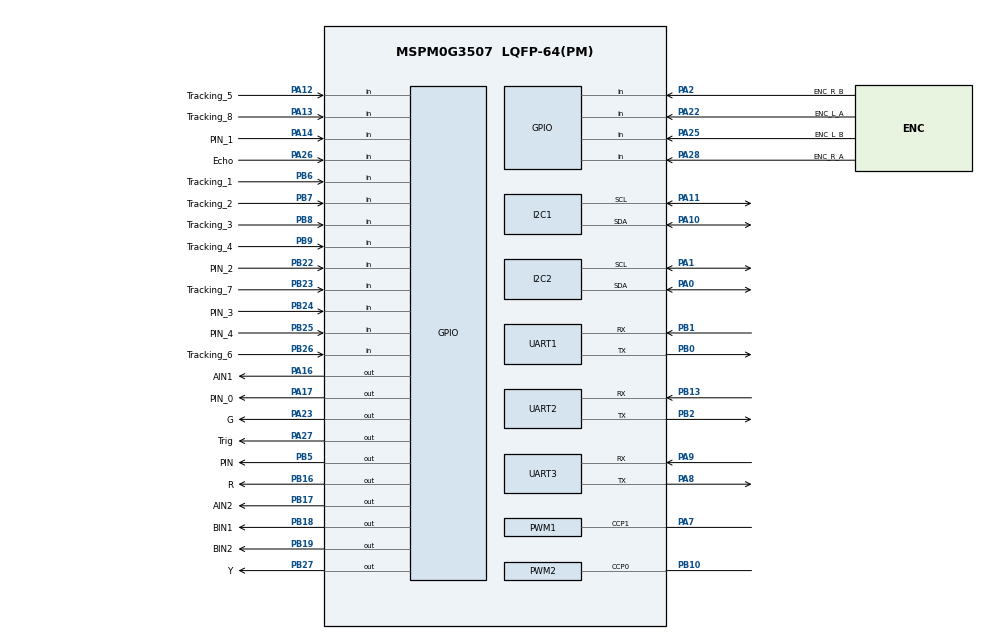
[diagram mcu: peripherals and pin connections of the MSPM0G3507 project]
/**
 * These arguments were used when this file was generated. They will be automatically applied on subsequent loads
 * via the GUI or CLI. Run CLI with '--help' for additional information on how to override these arguments.
 * @cliArgs --device "MSPM0G350X" --part "Default" --package "LQFP-64(PM)" --product "mspm0_sdk@2.10.00.04"
 * @v2CliArgs --device "MSPM0G3507" --package "LQFP-64(PM)" --product "mspm0_sdk@2.10.00.04"
 * @versions {"tool":"1.27.0+4565"}
 */

/**
 * Import the modules used in this configuration.
 */
const GPIO    = scripting.addModule("/ti/driverlib/GPIO", {}, false);
const GPIO1   = GPIO.addInstance();
const GPIO2   = GPIO.addInstance();
const GPIO3   = GPIO.addInstance();
const GPIO4   = GPIO.addInstance();
const GPIO5   = GPIO.addInstance();
const GPIO6   = GPIO.addInstance();
const GPIO7   = GPIO.addInstance();
const I2C     = scripting.addModule("/ti/driverlib/I2C", {}, false);
const I2C1    = I2C.addInstance();
const I2C2    = I2C.addInstance();
const PWM     = scripting.addModule("/ti/driverlib/PWM", {}, false);
const PWM1    = PWM.addInstance();
const PWM2    = PWM.addInstance();
const SYSCTL  = scripting.addModule("/ti/driverlib/SYSCTL");
const SYSTICK = scripting.addModule("/ti/driverlib/SYSTICK");
const TIMER   = scripting.addModule("/ti/driverlib/TIMER", {}, false);
const TIMER1  = TIMER.addInstance();
const UART    = scripting.addModule("/ti/driverlib/UART", {}, false);
const UART1   = UART.addInstance();
const UART2   = UART.addInstance();
const UART3   = UART.addInstance();

/**
 * Write custom configuration values to the imported modules.
 */
GPIO1.$name                               = "Motor_IO";
GPIO1.associatedPins.create(8);
GPIO1.associatedPins[0].$name             = "AIN1";
GPIO1.associatedPins[0].internalResistor  = "PULL_DOWN";
GPIO1.associatedPins[0].pin.$assign       = "PA16";
GPIO1.associatedPins[1].$name             = "AIN2";
GPIO1.associatedPins[1].internalResistor  = "PULL_DOWN";
GPIO1.associatedPins[1].pin.$assign       = "PB17";
GPIO1.associatedPins[2].$name             = "BIN1";
GPIO1.associatedPins[2].internalResistor  = "PULL_DOWN";
GPIO1.associatedPins[2].pin.$assign       = "PB18";
GPIO1.associatedPins[3].$name             = "BIN2";
GPIO1.associatedPins[3].internalResistor  = "PULL_DOWN";
GPIO1.associatedPins[3].pin.$assign       = "PB19";
GPIO1.associatedPins[4].$name             = "ENC_R_A";
GPIO1.associatedPins[4].direction         = "INPUT";
GPIO1.associatedPins[4].interruptEn       = true;
GPIO1.associatedPins[4].interruptPriority = "0";
GPIO1.associatedPins[4].polarity          = "RISE";
GPIO1.associatedPins[4].inputFilter       = "3_CYCLES";
GPIO1.associatedPins[4].pin.$assign       = "PA28";
GPIO1.associatedPins[5].$name             = "ENC_L_A";
GPIO1.associatedPins[5].direction         = "INPUT";
GPIO1.associatedPins[5].interruptEn       = true;
GPIO1.associatedPins[5].interruptPriority = "0";
GPIO1.associatedPins[5].polarity          = "RISE";
GPIO1.associatedPins[5].inputFilter       = "3_CYCLES";
GPIO1.associatedPins[5].pin.$assign       = "PA22";
GPIO1.associatedPins[6].$name             = "ENC_R_B";
GPIO1.associatedPins[6].direction         = "INPUT";
GPIO1.associatedPins[6].pin.$assign       = "PA2";
GPIO1.associatedPins[7].$name             = "ENC_L_B";
GPIO1.associatedPins[7].direction         = "INPUT";
GPIO1.associatedPins[7].pin.$assign       = "PA25";

const Board = scripting.addModule("/ti/driverlib/Board", {}, false);

GPIO2.$name                              = "Key";
GPIO2.associatedPins.create(4);
GPIO2.associatedPins[0].$name            = "PIN_1";
GPIO2.associatedPins[0].direction        = "INPUT";
GPIO2.associatedPins[0].internalResistor = "PULL_UP";
GPIO2.associatedPins[0].pin.$assign      = "PA14";
GPIO2.associatedPins[1].$name            = "PIN_2";
GPIO2.associatedPins[1].direction        = "INPUT";
GPIO2.associatedPins[1].internalResistor = "PULL_UP";
GPIO2.associatedPins[1].pin.$assign      = "PB22";
GPIO2.associatedPins[2].$name            = "PIN_3";
GPIO2.associatedPins[2].direction        = "INPUT";
GPIO2.associatedPins[2].internalResistor = "PULL_UP";
GPIO2.associatedPins[2].pin.$assign      = "PB24";
GPIO2.associatedPins[3].$name            = "PIN_4";
GPIO2.associatedPins[3].direction        = "INPUT";
GPIO2.associatedPins[3].internalResistor = "PULL_UP";
GPIO2.associatedPins[3].pin.$assign      = "PB25";

GPIO3.$name                              = "Tracking";
GPIO3.associatedPins.create(8);
GPIO3.associatedPins[0].$name            = "Tracking_1";
GPIO3.associatedPins[0].direction        = "INPUT";
GPIO3.associatedPins[0].internalResistor = "PULL_DOWN";
GPIO3.associatedPins[0].pin.$assign      = "PB6";
GPIO3.associatedPins[1].$name            = "Tracking_2";
GPIO3.associatedPins[1].internalResistor = "PULL_DOWN";
GPIO3.associatedPins[1].direction        = "INPUT";
GPIO3.associatedPins[1].pin.$assign      = "PB7";
GPIO3.associatedPins[2].$name            = "Tracking_3";
GPIO3.associatedPins[2].internalResistor = "PULL_DOWN";
GPIO3.associatedPins[2].direction        = "INPUT";
GPIO3.associatedPins[2].pin.$assign      = "PB8";
GPIO3.associatedPins[3].$name            = "Tracking_4";
GPIO3.associatedPins[3].internalResistor = "PULL_DOWN";
GPIO3.associatedPins[3].direction        = "INPUT";
GPIO3.associatedPins[3].pin.$assign      = "PB9";
GPIO3.associatedPins[4].$name            = "Tracking_5";
GPIO3.associatedPins[4].internalResistor = "PULL_DOWN";
GPIO3.associatedPins[4].direction        = "INPUT";
GPIO3.associatedPins[4].pin.$assign      = "PA12";
GPIO3.associatedPins[5].$name            = "Tracking_6";
GPIO3.associatedPins[5].internalResistor = "PULL_DOWN";
GPIO3.associatedPins[5].direction        = "INPUT";
GPIO3.associatedPins[5].pin.$assign      = "PB26";
GPIO3.associatedPins[6].$name            = "Tracking_7";
GPIO3.associatedPins[6].direction        = "INPUT";
GPIO3.associatedPins[6].internalResistor = "PULL_DOWN";
GPIO3.associatedPins[6].pin.$assign      = "PB23";
GPIO3.associatedPins[7].$name            = "Tracking_8";
GPIO3.associatedPins[7].internalResistor = "PULL_DOWN";
GPIO3.associatedPins[7].direction        = "INPUT";
GPIO3.associatedPins[7].pin.$assign      = "PA13";

GPIO4.$name                         = "SR04";
GPIO4.associatedPins.create(2);
GPIO4.associatedPins[0].$name       = "Trig";
GPIO4.associatedPins[0].pin.$assign = "PA27";
GPIO4.associatedPins[1].$name       = "Echo";
GPIO4.associatedPins[1].direction   = "INPUT";
GPIO4.associatedPins[1].pin.$assign = "PA26";

GPIO5.$name                         = "LED";
GPIO5.associatedPins.create(3);
GPIO5.associatedPins[0].$name       = "G";
GPIO5.associatedPins[0].pin.$assign = "PA23";
GPIO5.associatedPins[1].$name       = "Y";
GPIO5.associatedPins[1].pin.$assign = "PB27";
GPIO5.associatedPins[2].$name       = "R";
GPIO5.associatedPins[2].pin.$assign = "PB16";

GPIO6.$name                         = "Buzzer";
GPIO6.associatedPins[0].$name       = "PIN";
GPIO6.associatedPins[0].pin.$assign = "PB5";

GPIO7.$name                          = "GPIO_GRP_0";
GPIO7.associatedPins[0].$name        = "PIN_0";
GPIO7.associatedPins[0].initialValue = "SET";
GPIO7.associatedPins[0].pin.$assign  = "PA17";

I2C1.$name                             = "OLED";
I2C1.basicEnableController             = true;
I2C1.basicControllerStandardBusSpeed   = "Fast";
I2C1.peripheral.sdaPin.$assign         = "PA10";
I2C1.peripheral.sclPin.$assign         = "PA11";
I2C1.sdaPinConfig.$name                = "ti_driverlib_gpio_GPIOPinGeneric0";
I2C1.sdaPinConfig.hideOutputInversion  = scripting.forceWrite(false);
I2C1.sdaPinConfig.onlyInternalResistor = scripting.forceWrite(false);
I2C1.sdaPinConfig.passedPeripheralType = scripting.forceWrite("Digital");
I2C1.sclPinConfig.hideOutputInversion  = scripting.forceWrite(false);
I2C1.sclPinConfig.onlyInternalResistor = scripting.forceWrite(false);
I2C1.sclPinConfig.passedPeripheralType = scripting.forceWrite("Digital");
I2C1.sclPinConfig.$name                = "ti_driverlib_gpio_GPIOPinGeneric2";

I2C2.$name                             = "MPU6050_JY61P_Tracking";
I2C2.basicEnableController             = true;
I2C2.basicControllerStandardBusSpeed   = "Fast";
I2C2.intController                     = ["ARBITRATION_LOST","NACK","RXFIFO_TRIGGER","RX_DONE","TX_DONE"];
I2C2.peripheral.$assign                = "I2C0";
I2C2.peripheral.sdaPin.$assign         = "PA0";
I2C2.peripheral.sclPin.$assign         = "PA1";
I2C2.sdaPinConfig.hideOutputInversion  = scripting.forceWrite(false);
I2C2.sdaPinConfig.onlyInternalResistor = scripting.forceWrite(false);
I2C2.sdaPinConfig.passedPeripheralType = scripting.forceWrite("Digital");
I2C2.sdaPinConfig.$name                = "ti_driverlib_gpio_GPIOPinGeneric8";
I2C2.sclPinConfig.hideOutputInversion  = scripting.forceWrite(false);
I2C2.sclPinConfig.onlyInternalResistor = scripting.forceWrite(false);
I2C2.sclPinConfig.passedPeripheralType = scripting.forceWrite("Digital");
I2C2.sclPinConfig.$name                = "ti_driverlib_gpio_GPIOPinGeneric9";

PWM1.$name                              = "Motor_Left";
PWM1.clockDivider                       = 8;
PWM1.timerStartTimer                    = true;
PWM1.pwmMode                            = "EDGE_ALIGN_UP";
PWM1.ccIndex                            = [1];
PWM1.ccp1PinConfig.$name                = "ti_driverlib_gpio_GPIOPinGeneric5";
PWM1.ccp1PinConfig.direction            = scripting.forceWrite("OUTPUT");
PWM1.ccp1PinConfig.hideOutputInversion  = scripting.forceWrite(false);
PWM1.ccp1PinConfig.onlyInternalResistor = scripting.forceWrite(false);
PWM1.ccp1PinConfig.passedPeripheralType = scripting.forceWrite("Digital");
PWM1.peripheral.$assign                 = "TIMA0";
PWM1.peripheral.ccp1Pin.$assign         = "PA7";
PWM1.PWM_CHANNEL_1.$name                = "ti_driverlib_pwm_PWMTimerCC1";
PWM1.PWM_CHANNEL_1.ccValue              = 500;

PWM2.$name                              = "Motor_Right";
PWM2.clockDivider                       = 8;
PWM2.timerStartTimer                    = true;
PWM2.pwmMode                            = "EDGE_ALIGN_UP";
PWM2.ccIndex                            = [0];
PWM2.PWM_CHANNEL_0.$name                = "ti_driverlib_pwm_PWMTimerCC0";
PWM2.PWM_CHANNEL_0.dutyCycle            = 50;
PWM2.ccp0PinConfig.direction            = scripting.forceWrite("OUTPUT");
PWM2.ccp0PinConfig.hideOutputInversion  = scripting.forceWrite(false);
PWM2.ccp0PinConfig.onlyInternalResistor = scripting.forceWrite(false);
PWM2.ccp0PinConfig.passedPeripheralType = scripting.forceWrite("Digital");
PWM2.ccp0PinConfig.$name                = "ti_driverlib_gpio_GPIOPinGeneric4";
PWM2.peripheral.$assign                 = "TIMG0";
PWM2.peripheral.ccp0Pin.$assign         = "PB10";

SYSCTL.forceDefaultClkConfig = true;

SYSTICK.periodEnable    = true;
SYSTICK.interruptEnable = true;
SYSTICK.systickEnable   = true;
SYSTICK.period          = 32000;

TIMER1.$name              = "TIMER_0";
TIMER1.timerClkPrescale   = 100;
TIMER1.timerMode          = "PERIODIC";
TIMER1.interrupts         = ["ZERO"];
TIMER1.timerClkDiv        = 8;
TIMER1.timerStartTimer    = true;
TIMER1.interruptPriority  = "3";
TIMER1.timerPeriod        = "20ms";
TIMER1.peripheral.$assign = "TIMA1";

UART1.$name                            = "BlueTooth";
UART1.peripheral.$assign               = "UART0";
UART1.peripheral.rxPin.$assign         = "PB1";
UART1.peripheral.txPin.$assign         = "PB0";
UART1.txPinConfig.direction            = scripting.forceWrite("OUTPUT");
UART1.txPinConfig.hideOutputInversion  = scripting.forceWrite(false);
UART1.txPinConfig.onlyInternalResistor = scripting.forceWrite(false);
UART1.txPinConfig.passedPeripheralType = scripting.forceWrite("Digital");
UART1.txPinConfig.$name                = "ti_driverlib_gpio_GPIOPinGeneric12";
UART1.rxPinConfig.hideOutputInversion  = scripting.forceWrite(false);
UART1.rxPinConfig.onlyInternalResistor = scripting.forceWrite(false);
UART1.rxPinConfig.passedPeripheralType = scripting.forceWrite("Digital");
UART1.rxPinConfig.enableConfig         = true;
UART1.rxPinConfig.internalResistor     = "PULL_UP";
UART1.rxPinConfig.$name                = "ti_driverlib_gpio_GPIOPinGeneric13";

UART2.$name                            = "CY_Z";
UART2.targetBaudRate                   = 115200;
UART2.peripheral.$assign               = "UART3";
UART2.peripheral.rxPin.$assign         = "PB13";
UART2.peripheral.txPin.$assign         = "PB2";
UART2.txPinConfig.direction            = scripting.forceWrite("OUTPUT");
UART2.txPinConfig.hideOutputInversion  = scripting.forceWrite(false);
UART2.txPinConfig.onlyInternalResistor = scripting.forceWrite(false);
UART2.txPinConfig.passedPeripheralType = scripting.forceWrite("Digital");
UART2.txPinConfig.$name                = "ti_driverlib_gpio_GPIOPinGeneric14";
UART2.rxPinConfig.hideOutputInversion  = scripting.forceWrite(false);
UART2.rxPinConfig.onlyInternalResistor = scripting.forceWrite(false);
UART2.rxPinConfig.passedPeripheralType = scripting.forceWrite("Digital");
UART2.rxPinConfig.enableConfig         = true;
UART2.rxPinConfig.internalResistor     = "PULL_UP";
UART2.rxPinConfig.$name                = "ti_driverlib_gpio_GPIOPinGeneric15";

UART3.$name                            = "Debug_Ex";
UART3.targetBaudRate                   = 115200;
UART3.peripheral.rxPin.$assign         = "PA9";
UART3.peripheral.txPin.$assign         = "PA8";
UART3.txPinConfig.direction            = scripting.forceWrite("OUTPUT");
UART3.txPinConfig.hideOutputInversion  = scripting.forceWrite(false);
UART3.txPinConfig.onlyInternalResistor = scripting.forceWrite(false);
UART3.txPinConfig.passedPeripheralType = scripting.forceWrite("Digital");
UART3.txPinConfig.$name                = "ti_driverlib_gpio_GPIOPinGeneric3";
UART3.rxPinConfig.hideOutputInversion  = scripting.forceWrite(false);
UART3.rxPinConfig.onlyInternalResistor = scripting.forceWrite(false);
UART3.rxPinConfig.passedPeripheralType = scripting.forceWrite("Digital");
UART3.rxPinConfig.$name                = "ti_driverlib_gpio_GPIOPinGeneric7";

/**
 * Pinmux solution for unlocked pins/peripherals. This ensures that minor changes to the automatic solver in a future
 * version of the tool will not impact the pinmux you originally saw.  These lines can be completely deleted in order to
 * re-solve from scratch.
 */
Board.peripheral.$suggestSolution          = "DEBUGSS";
Board.peripheral.swclkPin.$suggestSolution = "PA20";
Board.peripheral.swdioPin.$suggestSolution = "PA19";
I2C1.peripheral.$suggestSolution           = "I2C1";
SYSCTL.peripheral.$suggestSolution         = "SYSCTL";
UART3.peripheral.$suggestSolution          = "UART1";
